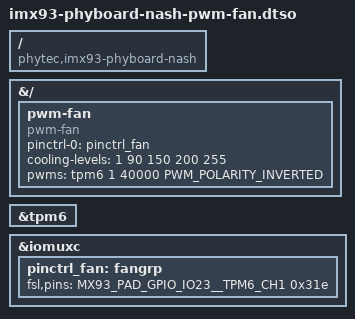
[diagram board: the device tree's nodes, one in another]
// SPDX-License-Identifier: GPL-2.0
/*
 * Copyright (C) 2024 PHYTEC Messtechnik GmbH
 * Author: Andrej Picej <andrej.picej@norik.com>
 */

#include <dt-bindings/pwm/pwm.h>
#include "imx93-pinfunc.h"

/dts-v1/;
/plugin/;

/ {
	compatible = "phytec,imx93-phyboard-nash";
};

&{/} {
	pwm-fan {
		compatible = "pwm-fan";
		pinctrl-names = "default";
		pinctrl-0 = <&pinctrl_fan>;
		cooling-levels = <1 90 150 200 255>;
		pwms = <&tpm6 1 40000 PWM_POLARITY_INVERTED>;
		#cooling-cells = <2>;
	};
};

&tpm6 {
	status = "okay";
};

&iomuxc {
	pinctrl_fan: fangrp {
		fsl,pins = <
			MX93_PAD_GPIO_IO23__TPM6_CH1		0x31e
		>;
	};
};
